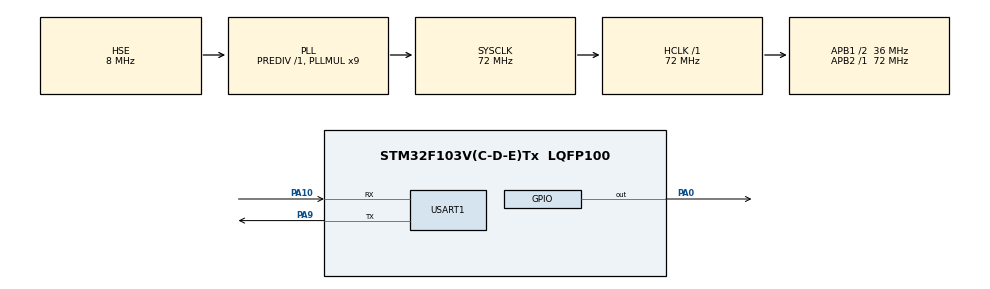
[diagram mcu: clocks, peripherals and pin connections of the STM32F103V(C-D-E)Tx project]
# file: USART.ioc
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Dma.Request0=USART1_RX
Dma.USART1_RX.0.Direction=DMA_PERIPH_TO_MEMORY
Dma.USART1_RX.0.Instance=DMA1_Channel5
Dma.USART1_RX.0.MemDataAlignment=DMA_MDATAALIGN_BYTE
Dma.USART1_RX.0.MemInc=DMA_MINC_ENABLE
Dma.USART1_RX.0.Mode=DMA_NORMAL
Dma.USART1_RX.0.PeriphDataAlignment=DMA_PDATAALIGN_BYTE
Dma.USART1_RX.0.PeriphInc=DMA_PINC_DISABLE
Dma.USART1_RX.0.Priority=DMA_PRIORITY_LOW
Mcu.Family=STM32F1
Mcu.Name=STM32F103V(C-D-E)Tx
Mcu.Package=LQFP100
NVIC.DMA1_Channel5_IRQn=true\:0\:0\:false\:false\:true\:false\:true\:true
NVIC.PriorityGroup=NVIC_PRIORITYGROUP_4
NVIC.USART1_IRQn=true\:0\:0\:false\:false\:true\:true\:true\:true
OSC_IN.Mode=HSE-External-Oscillator
OSC_IN.Signal=RCC_OSC_IN
OSC_OUT.Mode=HSE-External-Oscillator
OSC_OUT.Signal=RCC_OSC_OUT
PA0-WKUP.GPIO_ModeDefaultOutputPP=GPIO_MODE_OUTPUT_PP
PA0-WKUP.PinState=GPIO_PIN_SET
PA0-WKUP.Signal=GPIO_Output
PA10.Mode=Asynchronous
PA10.Signal=USART1_RX
PA13.Mode=Serial_Wire
PA13.Signal=SYS_JTMS-SWDIO
PA14.Mode=Serial_Wire
PA14.Signal=SYS_JTCK-SWCLK
PA9.Mode=Asynchronous
PA9.Signal=USART1_TX
PC14-OSC32_IN.Mode=LSE-External-Oscillator
PC14-OSC32_IN.Signal=RCC_OSC32_IN
PC15-OSC32_OUT.Mode=LSE-External-Oscillator
PC15-OSC32_OUT.Signal=RCC_OSC32_OUT
ProjectManager.HeapSize=0x200
ProjectManager.StackSize=0x400
ProjectManager.TargetToolchain=MDK-ARM V5
RCC.AHBFreq_Value=72000000
RCC.APB1CLKDivider=RCC_HCLK_DIV2
RCC.APB1Freq_Value=36000000
RCC.APB1TimFreq_Value=72000000
RCC.APB2Freq_Value=72000000
RCC.APB2TimFreq_Value=72000000
RCC.HCLKFreq_Value=72000000
RCC.PLLMUL=RCC_PLL_MUL9
RCC.PLLSourceVirtual=RCC_PLLSOURCE_HSE
RCC.SYSCLKFreq_VALUE=72000000
RCC.SYSCLKSource=RCC_SYSCLKSOURCE_PLLCLK
RCC.USBFreq_Value=72000000
USART1.VirtualMode=VM_ASYNC
board=custom

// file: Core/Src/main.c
/* USER CODE BEGIN Header */
/**
  ******************************************************************************
  * @file           : main.c
  * @brief          : Main program body
  * @author         : MCU Electronics Technology
  * @version        : V1.0
  * @date           : 2024-01-01
  * @note           : UART DMA Demo with IDLE detection
  ******************************************************************************
  */
/* USER CODE END Header */
#include "main.h"
#include "dma.h"
#include "usart.h"
#include "gpio.h"

/* USER CODE BEGIN Includes */
#include "stdio.h"
#include "string.h"
/* USER CODE END Includes */

/* USER CODE BEGIN PV */
uint8_t bsp_uart0_rx_buff[USART_BUFFER_SIZE];
/* USER CODE END PV */

void SystemClock_Config(void);

/* USER CODE BEGIN 0 */
void HAL_UARTEx_RxEventCallback(UART_HandleTypeDef *huart, uint16_t Size)
{
    if(huart->Instance == USART1)
    {
        // Add string terminator to the end of received data
        bsp_uart0_rx_buff[Size] = '\0';

        // Echo received data with proper format
        printf("[UART] Recv: %s", bsp_uart0_rx_buff);

        // If the received data doesn't end with \r\n, add it
        if (Size < 2 || bsp_uart0_rx_buff[Size-2] != '\r' || bsp_uart0_rx_buff[Size-1] != '\n') {
            printf("\r\n");
        }

        // Restart DMA reception
        HAL_UARTEx_ReceiveToIdle_DMA(&huart1, bsp_uart0_rx_buff, USART_BUFFER_SIZE);
        __HAL_DMA_DISABLE_IT(&hdma_usart1_rx, DMA_IT_HT);
    }
}

#ifdef __GNUC__
#define PUTCHAR_PROTOTYPE int __io_putchar(int ch)
#else
#define PUTCHAR_PROTOTYPE int fputc(int ch, FILE *f)
#endif

// Redirect printf to UART
PUTCHAR_PROTOTYPE
{
    HAL_UART_Transmit(&huart1, (uint8_t *)&ch, 1, HAL_MAX_DELAY);
    return ch;
}
/* USER CODE END 0 */

int main(void)
{

  /* MCU Configuration--------------------------------------------------------*/

  /* Reset of all peripherals, Initializes the Flash interface and the Systick. */
  HAL_Init();

  /* Configure the system clock */
  SystemClock_Config();

  /* Initialize all configured peripherals */
  MX_GPIO_Init();
  MX_DMA_Init();
  MX_USART1_UART_Init();
  /* USER CODE BEGIN 2 */

  printf("************************************************\r\n");
  printf("*     Welcome to MCU Electronics Technology     *\r\n");
  printf("*          Mcore_MainBoard V1.0                *\r\n");
  printf("************************************************\r\n");
  printf("UART Configuration:\r\n");
  printf("- Baud Rate: 115200\r\n");
  printf("- Data Bits: 8\r\n");
  printf("- Stop Bits: 1\r\n");
  printf("- Parity: None\r\n");
  printf("\r\nSystem is ready. Please input any characters...\r\n\r\n");

  // Start DMA reception
  HAL_UARTEx_ReceiveToIdle_DMA(&huart1, bsp_uart0_rx_buff, USART_BUFFER_SIZE);
  __HAL_DMA_DISABLE_IT(&hdma_usart1_rx, DMA_IT_HT);  // Disable DMA half transfer interrupt
  /* USER CODE END 2 */

  /* Infinite loop */
  while (1)
  {

    /* USER CODE BEGIN 3 */
    HAL_GPIO_TogglePin(GPIOA, GPIO_PIN_0);  // Toggle LED to indicate system is running
    HAL_Delay(500);  // Blink every 500ms
  }
  /* USER CODE END 3 */
}

void SystemClock_Config(void)
{
  RCC_OscInitTypeDef RCC_OscInitStruct = {0};
  RCC_ClkInitTypeDef RCC_ClkInitStruct = {0};

  /** Initializes the RCC Oscillators according to the specified parameters
  * in the RCC_OscInitTypeDef structure.
  */
  RCC_OscInitStruct.OscillatorType = RCC_OSCILLATORTYPE_HSE;
  RCC_OscInitStruct.HSEState = RCC_HSE_ON;
  RCC_OscInitStruct.HSEPredivValue = RCC_HSE_PREDIV_DIV1;
  RCC_OscInitStruct.HSIState = RCC_HSI_ON;
  RCC_OscInitStruct.PLL.PLLState = RCC_PLL_ON;
  RCC_OscInitStruct.PLL.PLLSource = RCC_PLLSOURCE_HSE;
  RCC_OscInitStruct.PLL.PLLMUL = RCC_PLL_MUL9;
  if (HAL_RCC_OscConfig(&RCC_OscInitStruct) != HAL_OK)
  {
    Error_Handler();
  }

  /** Initializes the CPU, AHB and APB buses clocks
  */
  RCC_ClkInitStruct.ClockType = RCC_CLOCKTYPE_HCLK|RCC_CLOCKTYPE_SYSCLK
                              |RCC_CLOCKTYPE_PCLK1|RCC_CLOCKTYPE_PCLK2;
  RCC_ClkInitStruct.SYSCLKSource = RCC_SYSCLKSOURCE_PLLCLK;
  RCC_ClkInitStruct.AHBCLKDivider = RCC_SYSCLK_DIV1;
  RCC_ClkInitStruct.APB1CLKDivider = RCC_HCLK_DIV2;
  RCC_ClkInitStruct.APB2CLKDivider = RCC_HCLK_DIV1;

  if (HAL_RCC_ClockConfig(&RCC_ClkInitStruct, FLASH_LATENCY_2) != HAL_OK)
  {
    Error_Handler();
  }
}

void Error_Handler(void)
{
  __disable_irq();
  while (1)
  {
  }
}
